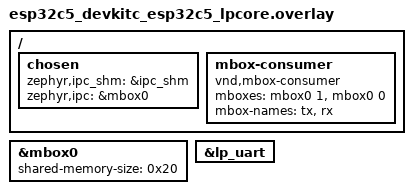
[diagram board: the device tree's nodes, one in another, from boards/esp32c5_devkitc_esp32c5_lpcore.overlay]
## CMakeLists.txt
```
# SPDX-License-Identifier: Apache-2.0

cmake_minimum_required(VERSION 3.20.0)
find_package(Zephyr REQUIRED HINTS $ENV{ZEPHYR_BASE})
project(zephyr_hd_test_remote)

target_sources(app PRIVATE src/main.c)
```

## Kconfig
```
config ESP_BIST_RUNTIME_TEST_INTERVAL_MS
	int "Runtime test interval (ms)"
	default 500
	help
	  Interval in milliseconds between periodic runtime BIST test rounds
	  on the LP core.

source "Kconfig.zephyr"
```

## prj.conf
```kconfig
CONFIG_MBOX=y
CONFIG_SERIAL=y
CONFIG_PRINTK=y
CONFIG_MAIN_STACK_SIZE=1024
CONFIG_ISR_STACK_SIZE=512
CONFIG_IDLE_STACK_SIZE=32
CONFIG_OUTPUT_DISASSEMBLY=y
# BIST tests to run on the LP core
CONFIG_ESP_BIST=y
CONFIG_ESP_BIST_CPU_REG_TEST=y
CONFIG_ESP_BIST_STACK_TEST=y
CONFIG_ESP_BIST_MEMORY_RAM_TEST=y
# 64-word partitions → 512 B Abraham pair + 512 B backup; fits LP SRAM with HDA.
CONFIG_ESP_BIST_RAM_PARTITION_SIZE=64
CONFIG_ESP_BIST_MEMORY_FLASH_TEST=y
# Host Diagnostics companion (LP side)
CONFIG_ESP_BIST_HOST_DIAGNOSTICS=y
CONFIG_ESP_BIST_HD_AUDIT_QA=y
CONFIG_ESP_BIST_HD_AUDIT_CHECKPOINT=y
CONFIG_ESP_BIST_HD_CHECKPOINT_PERIOD_LOOPS=20
CONFIG_ESP_BIST_HD_AUDIT_IRQ_LATENCY=y
CONFIG_ESP_BIST_HD_IRQ_LATENCY_BUDGET_US=5000
CONFIG_ESP_BIST_HD_AUDIT=y
CONFIG_ESP_BIST_HD_AUDIT_CPU=y
CONFIG_ESP_BIST_HD_AUDIT_CSR=y
CONFIG_ESP_BIST_HD_AUDIT_RAM=y
CONFIG_ESP_BIST_HD_AGENT_READY_TIMEOUT_US=5000000
# Runtime round must stay well inside the 50 ms LP WDT window.
CONFIG_ESP_BIST_RUNTIME_TEST_INTERVAL_MS=10
```

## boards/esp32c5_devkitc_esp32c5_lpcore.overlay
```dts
/*
 * Copyright (c) 2026 Espressif Systems (Shanghai) Co., Ltd.
 *
 * SPDX-License-Identifier: Apache-2.0
 */

/ {
	chosen {
		zephyr,ipc_shm = &ipc_shm;
		zephyr,ipc = &mbox0;
	};

	mbox-consumer {
		compatible = "vnd,mbox-consumer";
		mboxes = <&mbox0 1>, <&mbox0 0>;
		mbox-names = "tx", "rx";
	};
};

&mbox0 {
	status = "okay";
	/* One Host Diagnostics frame (4 words) per direction. */
	shared-memory-size = <0x20>;
};

&lp_uart {
	status = "okay";
};
```

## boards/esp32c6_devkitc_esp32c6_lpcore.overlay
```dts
/*
 * Copyright (c) 2026 Espressif Systems (Shanghai) Co., Ltd.
 *
 * SPDX-License-Identifier: Apache-2.0
 */

/ {
	chosen {
		zephyr,ipc_shm = &ipc_shm;
		zephyr,ipc = &mbox0;
	};

	mbox-consumer {
		compatible = "vnd,mbox-consumer";
		mboxes = <&mbox0 1>, <&mbox0 0>;
		mbox-names = "tx", "rx";
	};
};

&mbox0 {
	/* One Host Diagnostics frame (4 words) per direction. */
	shared-memory-size = <0x20>;
};

&lp_uart {
	status = "okay";
};
```

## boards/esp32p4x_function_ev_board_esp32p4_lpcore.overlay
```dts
/*
 * Copyright (c) 2026 Espressif Systems (Shanghai) Co., Ltd.
 *
 * SPDX-License-Identifier: Apache-2.0
 */

/ {
	chosen {
		zephyr,ipc_shm = &ipc_shm;
		zephyr,ipc = &mbox0;
	};

	mbox-consumer {
		compatible = "vnd,mbox-consumer";
		mboxes = <&mbox0 1>, <&mbox0 0>;
		mbox-names = "tx", "rx";
	};
};

&mbox0 {
	status = "okay";
	shared-memory-size = <0x20>;
};

&lp_uart {
	status = "okay";
};
```

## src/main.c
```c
/*
 * Copyright (c) 2026 Espressif Systems (Shanghai) Co., Ltd.
 *
 * SPDX-License-Identifier: Apache-2.0
 */

/*
 * LP-core entry for the Host Diagnostics fail-closed validation app.
 *
 * Identical to samples/zephyr/remote/src/main.c on purpose: the companion is
 * the element under test, so it is built and run exactly as a product would.
 * Every difference between the happy path and the fault cases lives on the HP
 * side.
 *
 * The LP image has no system clock, so pacing uses the companion port delay
 * rather than k_msleep().
 */

#include <zephyr/kernel.h>

#include <bist_hd_comp_port.h>
#include <bist_hd_companion.h>

#define RUNTIME_INTERVAL_US (CONFIG_ESP_BIST_RUNTIME_TEST_INTERVAL_MS * 1000)

int main(void)
{
	if (bist_hd_companion_init() != 0) {
		return 0;
	}

	while (1) {
		bist_hd_companion_loop();
		bist_hd_comp_port_delay_us(RUNTIME_INTERVAL_US);
	}

	return 0;
}
```
